# nrf9120_mlm1_modem register map
Vendor: Nordic Semiconductor; Series: nrf91; File version: 1
CPU: CM4 r0p1, little endian, MPU, no FPU, 3 interrupt priority bits
Registers are 32-bit, read-write, reset 0x0 unless marked. A register's access mark holds for its fields unless they carry their own. Offsets are from the block's base; [hi:lo] are bit positions; {n}, {i} and the like mark numbered series; 'fields as' and 'values as' point back to an identical list.

## GPIOTE0 — GPIO Tasks and Events 0
Base 0x40030000
Same registers: GPIOTE1 0x40031000
{0x0+4i} TASKS_OUT[{i}] (i=0..0) wo — Description collection: Task for writing to pin specified in CONFIG[n].PSEL. Action on pin is configured in CONFIG[n].POLARITY.
  [0] TASKS_OUT — Task for writing to pin specified in CONFIG[n].PSEL. Action on pin is configured in CONFIG[n].POLARITY.
    1=Trigger task
{0x30+4i} TASKS_SET[{i}] (i=0..0) wo — Description collection: Task for writing to pin specified in CONFIG[n].PSEL. Action on pin is to set it high.
  [0] TASKS_SET — Task for writing to pin specified in CONFIG[n].PSEL. Action on pin is to set it high.
    1=Trigger task
{0x60+4i} TASKS_CLR[{i}] (i=0..0) wo — Description collection: Task for writing to pin specified in CONFIG[n].PSEL. Action on pin is to set it low.
  [0] TASKS_CLR — Task for writing to pin specified in CONFIG[n].PSEL. Action on pin is to set it low.
    1=Trigger task
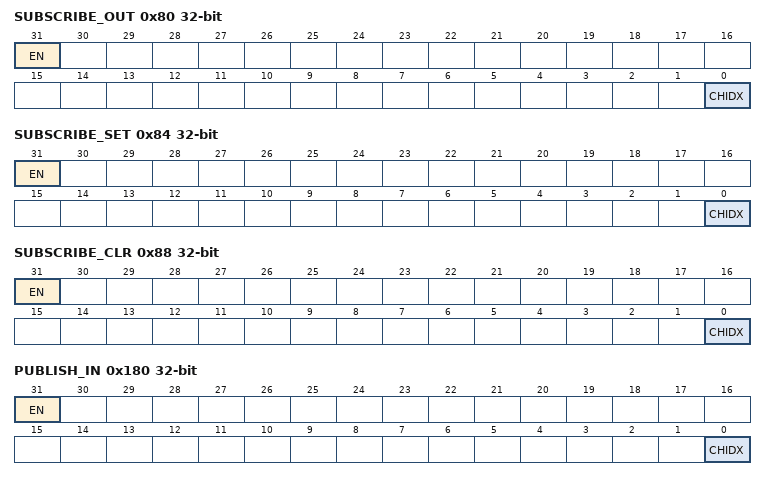
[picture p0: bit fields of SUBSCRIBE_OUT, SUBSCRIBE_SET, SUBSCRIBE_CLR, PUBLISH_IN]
0x80 SUBSCRIBE_OUT — Subscribe configuration for TASKS_OUT
  [31] EN — Channel the TASKS_OUT will subscribe to.
    0=Disabled (Disable subscription); 1=Enabled (Enable subscription)
  [0] CHIDX — Channel the TASKS_OUT will subscribe to.
0x84 SUBSCRIBE_SET — Subscribe configuration for TASKS_SET
  [31] EN — Channel the TASKS_SET will subscribe to.
    values as SUBSCRIBE_OUT.EN
  [0] CHIDX — Channel the TASKS_SET will subscribe to.
0x88 SUBSCRIBE_CLR — Subscribe configuration for TASKS_CLR
  [31] EN — Channel the TASKS_CLR will subscribe to.
    values as SUBSCRIBE_OUT.EN
  [0] CHIDX — Channel the TASKS_CLR will subscribe to.
{0x100+4i} EVENTS_IN[{i}] (i=0..0) — Description collection: Event generated from pin specified in CONFIG[n].PSEL
  [0] EVENTS_IN — Event generated from pin specified in CONFIG[n].PSEL
    0=NotGenerated (Event not generated); 1=Generated (Event generated)
0x17C EVENTS_PORT — Event generated from multiple input GPIO pins with SENSE mechanism enabled
  [0] EVENTS_PORT
    values as EVENTS_IN[0].EVENTS_IN
0x180 PUBLISH_IN — Publish configuration for EVENTS_IN
  [31] EN — Channel the EVENTS_TICK will subscribe to.
    values as SUBSCRIBE_OUT.EN
  [0] CHIDX — Channel the EVENTS_IN will subscribe to.
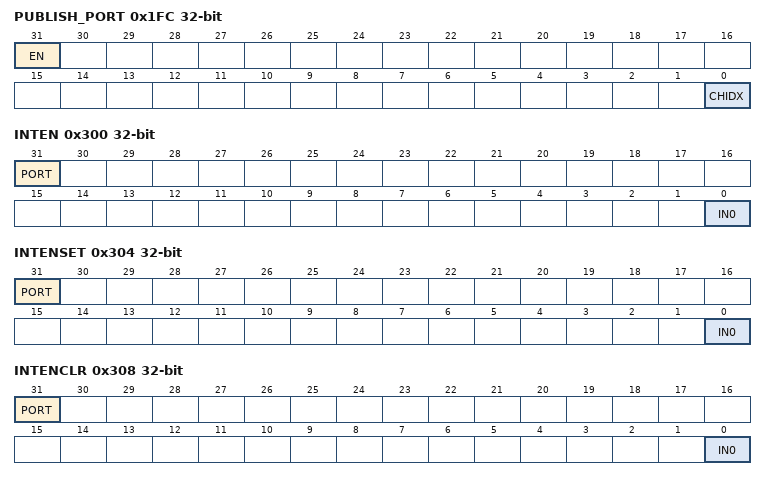
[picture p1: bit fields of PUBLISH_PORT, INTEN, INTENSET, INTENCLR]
0x1FC PUBLISH_PORT — Publish configuration for EVENTS_IN
  fields as PUBLISH_IN
0x300 INTEN — Enable or disable interrupt
  [31] PORT — Enable or disable interrupt for event PORT
    0=Disabled; 1=Enabled
  [0] IN0 — Enable or disable interrupt for event IN[0]
    0=Disabled; 1=Enabled
0x304 INTENSET — Enable interrupt
  [31] PORT — Write '1' to enable interrupt for event PORT
    on read: 0=Disabled (Read: Disabled); 1=Enabled (Read: Enabled) | on write: 1=Set (Enable)
  [0] IN0 — Write '1' to enable interrupt for event IN[0]
    values as PORT
0x308 INTENCLR — Disable interrupt
  [31] PORT — Write '1' to disable interrupt for event PORT
    on read: 0=Disabled (Read: Disabled); 1=Enabled (Read: Enabled) | on write: 1=Clear (Disable)
  [0] IN0 — Write '1' to disable interrupt for event IN[0]
    values as PORT
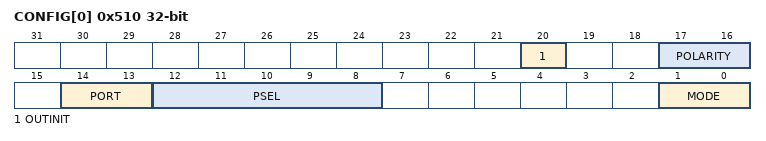
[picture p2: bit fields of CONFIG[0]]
{0x510+4i} CONFIG[{i}] (i=0..0) — Description collection: Configuration for OUT[n], SET[n] and CLR[n] tasks and IN[n] event
  [20] OUTINIT — When in task mode: Initial value of the output when the GPIOTE channel is configured. When in event mode: No effect.
    0=Low (Task mode: Initial value of pin before task triggering is low); 1=High (Task mode: Initial value of pin before task triggering is high)
  [17:16] POLARITY — When In task mode: Operation to be performed on output when OUT[n] task is triggered. When In event mode: Operation on input that shall trigger IN[n] event.
    0=None (Task mode: No effect on pin from OUT[n] task. Event mode: no IN[n] event generated on pin activity.); 1=LoToHi (Task mode: Set pin from OUT[n] task. Event mode: Generate IN[n] event when rising edge on pin.); 2=HiToLo (Task mode: Clear pin from OUT[n] task. Event mode: Generate IN[n] event when falling edge on pin.); 3=Toggle (Task mode: Toggle pin from OUT[n]. Event mode: Generate IN[n] when any change on pin.)
  [14:13] PORT — Port number
  [12:8] PSEL — GPIO number associated with SET[n], CLR[n] and OUT[n] tasks and IN[n] event
  [1:0] MODE
    0=Disabled. Pin specified by PSEL will not be acquired by the GPIOTE module.; 1=Event mode; 3=Task mode
{0x600+4i} DEBOUNCE[{i}] (i=0..0) — Description collection: Debounce mode for GPIOTE channel n
  [0] MODE
    0=Mode 0: nRF52 debounce method; 1=Mode 1: nRF51 legacy debounce method
0xFFC POWER reset 0x1 — Peripheral power control
  [0] POWER — Peripheral power control. The peripheral and its registers will be reset to its initial state by switching the peripheral off and then back on again.
    0=Disabled (Peripheral is powered off); 1=Enabled (Peripheral is powered on)
